# DSS1_OVR2 register map
Vendor: Texas Instruments
Peripheral module from a debugger description file (folder am62P).
Registers are 32-bit, access per field, reset 0x0 unless marked. A register's access mark holds for its fields unless they carry their own. Offsets are as the file gives them; lines under a group give offsets from that group; [hi:lo] are bit positions; {n}, {i} and the like mark numbered series; 'fields as' and 'values as' point back to an identical list; <NAME> marks a mode.

## DSS1_OVR2
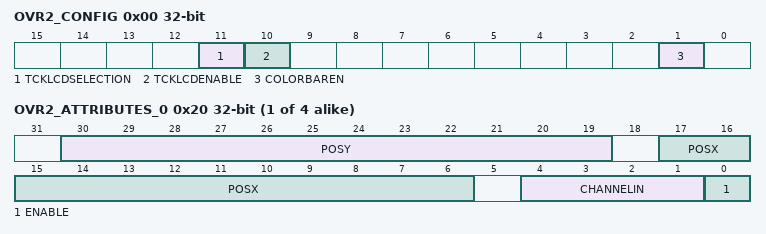
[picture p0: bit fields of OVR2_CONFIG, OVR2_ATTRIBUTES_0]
0x00 OVR2_CONFIG — The control register configures the Display Controller module for the VP output. Shadow register
  [11] TCKLCDSELECTION rw — Transparency Color Key Selection
  [10] TCKLCDENABLE rw — Transparency Color Key Enable
  [1] COLORBAREN rw — Enable the Color-Bar
0x08 OVR2_DEFAULT_COLOR rw — The control register configures the default solid background color LSB[31:0]. Shadow register
  [31:0] DEFAULTCOLOR — 32-bit LSB of ARGB background color
0x0C OVR2_DEFAULT_COLOR2 — The control register configures the default solid background color MSB[47:32]. Shadow register
  [15:0] DEFAULTCOLOR rw — 16-bit MSB of ARGB background color
0x10 OVR2_TRANS_COLOR_MAX rw — The register sets the max transparency color value for the overlays. Shadow register
  [31:0] TRANSCOLORKEY — LSB[31:0]. Transparency Color Key Value in 36-bit RGB format
0x14 OVR2_TRANS_COLOR_MAX2 — The register sets the max transparency color value for the overlays. Shadow register
  [3:0] TRANSCOLORKEY rw — MSB[35:32]. Transparency Color Key Value in 36-bit RGB format
0x18 OVR2_TRANS_COLOR_MIN rw — The register sets the min transparency color value for the overlays. Shadow register
  fields as OVR2_TRANS_COLOR_MAX
0x1C OVR2_TRANS_COLOR_MIN2 — The register sets the min transparency color value for the overlays. Shadow register
  fields as OVR2_TRANS_COLOR_MAX2
{0x20+4i} OVR2_ATTRIBUTES_{i} (i=0..3) — The register configures the attributes of layer-{i}, ZORDER= {i}, of the Overlay manager. Shadow register
  [30:19] POSY rw — Y position of the layer. Encoded value [from 0 to 4095] to specify the Y position of the layer on the screen. The line at the top has the Y-position 0
  [17:6] POSX rw — X position of the layer. Encoded value [from 0 to 4095] to specify the X position of the layer on the screen. The first pixel on the left of the screen has the X-position 0
  [4:1] CHANNELIN rw — Input channel connected to Layer
  [0] ENABLE rw — Layer Enable
